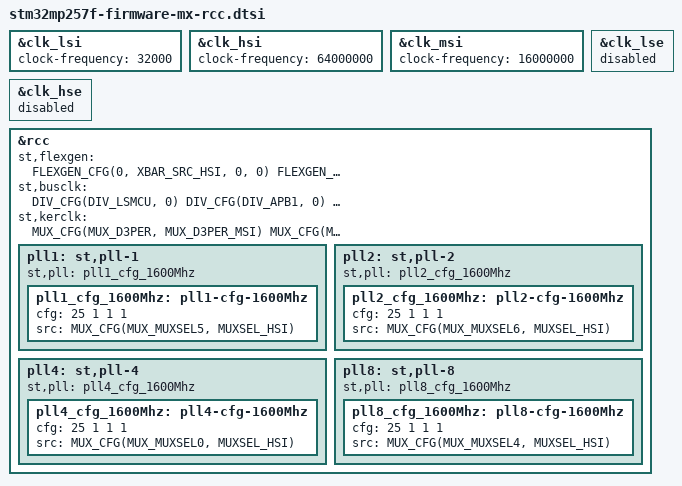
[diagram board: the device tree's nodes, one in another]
// SPDX-License-Identifier: (GPL-2.0-or-later OR BSD-3-Clause)
/*
 * Copyright (C) 2025, STMicroelectronics - All Rights Reserved
 * Author: STM32CubeMX code generation for STMicroelectronics.
 */

/* For more information on Device Tree configuration, please refer to
 * https://wiki.st.com/stm32mpu/wiki/Category:Device_tree_configuration
 */

&clk_lsi {
	clock-frequency = <32000>;

	/* USER CODE BEGIN clk_lsi */
	/* USER CODE END clk_lsi */
};
&clk_hsi {
	clock-frequency = <64000000>;

	/* USER CODE BEGIN clk_hsi */
	/* USER CODE END clk_hsi */
};
&clk_msi {
	clock-frequency = <16000000>;

	/* USER CODE BEGIN clk_msi */
	/* USER CODE END clk_msi */
};
&clk_lse {
	status = "disabled";

	/* USER CODE BEGIN clk_lse */
	/* USER CODE END clk_lse */
};
&clk_hse {
	status = "disabled";

	/* USER CODE BEGIN clk_hse */
	/* USER CODE END clk_hse */
};

&rcc {

	st,flexgen = <

		FLEXGEN_CFG(0, XBAR_SRC_HSI, 0, 0)
		FLEXGEN_CFG(1, XBAR_SRC_HSI, 0, 0)
		FLEXGEN_CFG(2, XBAR_SRC_HSI, 0, 0)
		FLEXGEN_CFG(3, XBAR_SRC_HSI, 0, 0)
		FLEXGEN_CFG(4, XBAR_SRC_HSI, 0, 0)
		FLEXGEN_CFG(5, XBAR_SRC_HSI, 0, 0)
		FLEXGEN_CFG(6, XBAR_SRC_HSI, 0, 0)
		FLEXGEN_CFG(12, XBAR_SRC_HSI_KER, 0, 0)
		FLEXGEN_CFG(13, XBAR_SRC_HSI_KER, 0, 0)
		FLEXGEN_CFG(33, XBAR_SRC_HSI_KER, 0, 0)
		FLEXGEN_CFG(43, XBAR_SRC_PLL8, 0, 24)
		FLEXGEN_CFG(44, XBAR_SRC_PLL8, 0, 7)
		FLEXGEN_CFG(45, XBAR_SRC_PLL8, 0, 3)
		FLEXGEN_CFG(54, XBAR_SRC_PLL8, 0, 0)
		FLEXGEN_CFG(56, XBAR_SRC_HSI_KER, 0, 0)
		FLEXGEN_CFG(57, XBAR_SRC_PLL4, 0, 0)
		FLEXGEN_CFG(59, XBAR_SRC_PLL8, 0, 2)
		FLEXGEN_CFG(60, XBAR_SRC_PLL8, 0, 0)
		FLEXGEN_CFG(63, XBAR_SRC_HSI_KER, 0, 0)
	>;

	st,busclk = <
		DIV_CFG(DIV_LSMCU, 0)
		DIV_CFG(DIV_APB1, 0)
		DIV_CFG(DIV_APB2, 0)
		DIV_CFG(DIV_APB3, 0)
		DIV_CFG(DIV_APB4, 0)
		DIV_CFG(DIV_APBDBG, 0)
	>;

	st,kerclk = <
		MUX_CFG(MUX_D3PER, MUX_D3PER_MSI)
		MUX_CFG(MUX_USB2PHY1, MUX_USB2PHY1_FLEX57)

	>;

	pll1:st,pll-1 {
		st,pll = < &pll1_cfg_1600Mhz >;

		pll1_cfg_1600Mhz: pll1-cfg-1600Mhz{
			cfg = <25 1 1 1>;
			src = <MUX_CFG(MUX_MUXSEL5, MUXSEL_HSI)>;
		};
		/* USER CODE BEGIN pll1 */
		/* USER CODE END pll1 */
	};

	pll2:st,pll-2 {
		st,pll = < &pll2_cfg_1600Mhz >;

		pll2_cfg_1600Mhz: pll2-cfg-1600Mhz{
			cfg = <25 1 1 1>;
			src = <MUX_CFG(MUX_MUXSEL6, MUXSEL_HSI)>;
		};
		/* USER CODE BEGIN pll2 */
		/* USER CODE END pll2 */
	};

	pll4:st,pll-4 {
		st,pll = < &pll4_cfg_1600Mhz >;

		pll4_cfg_1600Mhz: pll4-cfg-1600Mhz{
			cfg = <25 1 1 1>;
			src = <MUX_CFG(MUX_MUXSEL0, MUXSEL_HSI)>;
		};
		/* USER CODE BEGIN pll4 */
		/* USER CODE END pll4 */
	};

	pll8:st,pll-8 {
		st,pll = < &pll8_cfg_1600Mhz >;

		pll8_cfg_1600Mhz: pll8-cfg-1600Mhz{
			cfg = <25 1 1 1>;
			src = <MUX_CFG(MUX_MUXSEL4, MUXSEL_HSI)>;
		};
		/* USER CODE BEGIN pll8 */
		/* USER CODE END pll8 */
	};

	/* USER CODE BEGIN rcc */
	/* USER CODE END rcc */
};
